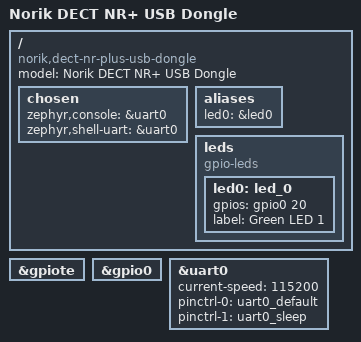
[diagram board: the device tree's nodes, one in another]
/*
 * Copyright (c) 2026 Norik Systems
 *
 * SPDX-License-Identifier: Apache-2.0
 */

#include "dect_nr_plus_usb_dongle-pinctrl.dtsi"

/ {
	model = "Norik DECT NR+ USB Dongle";
	compatible = "norik,dect-nr-plus-usb-dongle";

	chosen {
		zephyr,console = &uart0;
		zephyr,shell-uart = &uart0;
	};

	aliases {
		led0 = &led0;
	};

	leds {
		compatible = "gpio-leds";

		led0: led_0 {
			gpios = <&gpio0 20 GPIO_ACTIVE_HIGH>;
			label = "Green LED 1";
		};
	};
};

&gpiote {
	status = "okay";
};

&gpio0 {
	status = "okay";
};

&uart0 {
	status = "okay";
	current-speed = <115200>;
	pinctrl-0 = <&uart0_default>;
	pinctrl-1 = <&uart0_sleep>;
	pinctrl-names = "default", "sleep";
};

/* Include default memory partition configuration file */
#include <nordic/nrf91xx_partition.dtsi>
